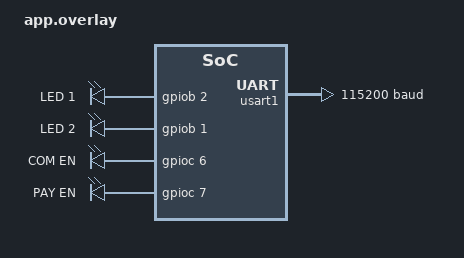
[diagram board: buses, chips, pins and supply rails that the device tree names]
/ {
	aliases {
		led0 = &led_1;
		led1 = &led_2;
		com-en = &com_en;
		pay-en = &pay_en;
	};

	leds {
		compatible = "gpio-leds";
		led_1: led_1 {
			gpios = <&gpiob 2 GPIO_ACTIVE_HIGH>;
			label = "LED 1";
		};
		led_2: led_2 {
			gpios = <&gpiob 1 GPIO_ACTIVE_HIGH>;
			label = "LED 2";
		};
		com_en: com_en {
			gpios = <&gpioc 6 GPIO_ACTIVE_HIGH>;
			label = "COM EN";
		};
		pay_en: pay_en {
			gpios = <&gpioc 7 GPIO_ACTIVE_HIGH>;
			label = "PAY EN";
		};
	};
};

&usart1 {
	status = "okay";
	current-speed = <115200>;
};
